# EFM32GG380F1024 register map
File version: 5.8.2
CPU: CM3 r2p1, little endian, MPU, no FPU, 3 interrupt priority bits
Registers are 32-bit, read-write, reset 0x0 unless marked. A register's access mark holds for its fields unless they carry their own. Offsets are from the block's base; [hi:lo] are bit positions; {n}, {i} and the like mark numbered series; 'fields as' and 'values as' point back to an identical list.

## EMU
Base 0x400C6000
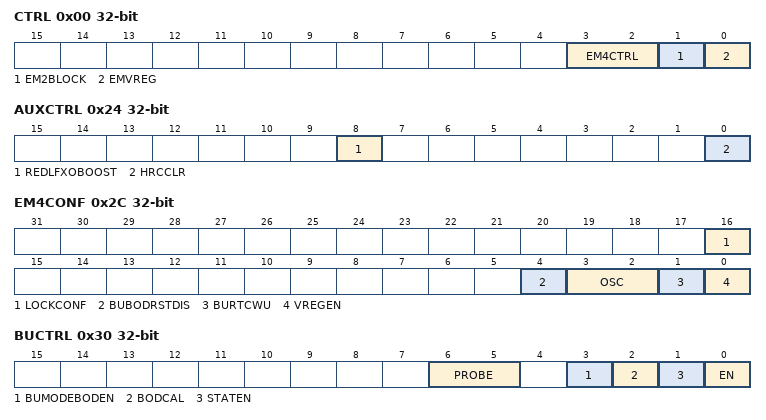
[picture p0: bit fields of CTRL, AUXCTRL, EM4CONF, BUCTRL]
0x00 CTRL — Control Register
  [3:2] EM4CTRL — Energy Mode 4 Control
  [1] EM2BLOCK — Energy Mode 2 Block
  [0] EMVREG — Energy Mode Voltage Regulator Control
0x04 MEMCTRL — Memory Control Register
  [2:0] POWERDOWN — RAM block power-down
    4=BLK3 (Power down RAM block 3 (address range 0x20018000-0x2001FFFF).); 6=BLK23 (Power down RAM blocks 2-3 (address range 0x20010000-0x2001FFFF).); 7=BLK123 (Power down RAM blocks 1-3 (address range 0x20008000-0x2001FFFF).)
0x08 LOCK — Configuration Lock Register
  [15:0] LOCKKEY — Configuration Lock Key
    0=UNLOCKED; 1=LOCKED
0x24 AUXCTRL — Auxiliary Control Register
  [8] REDLFXOBOOST — Reduce LFXO Start-up Boost Current
  [0] HRCCLR — Hard Reset Cause Clear
0x2C EM4CONF — Energy mode 4 configuration register
  [16] LOCKCONF — EM4 configuration lock enable
  [4] BUBODRSTDIS — Disable reset from Backup BOD in EM4
  [3:2] OSC — Select EM4 duty oscillator
    0=ULFRCO (ULFRCO is available.); 1=LFRCO (LFRCO is available. Can only be set if LFRCO is running before EM4/backup entry.); 2=LFXO (LFXO is available. Can only be set if LFXO is available before EM4/backup entry.)
  [1] BURTCWU — Backup RTC EM4 wakeup enable
  [0] VREGEN — EM4 voltage regulator enable
0x30 BUCTRL — Backup Power configuration register
  [6:5] PROBE — Voltage probe select
    0=DISABLE (Disable voltage probe.); 1=VDDDREG (Connect probe to VDD_DREG.); 2=BUIN (Connect probe to BU_IN.); 3=BUOUT (Connect probe to BU_OUT.)
  [3] BUMODEBODEN — Enable brown out detection on BU_VIN when in backup mode
  [2] BODCAL — Enable BOD calibration mode
  [1] STATEN — Enable backup mode status export
  [0] EN — Enable backup mode
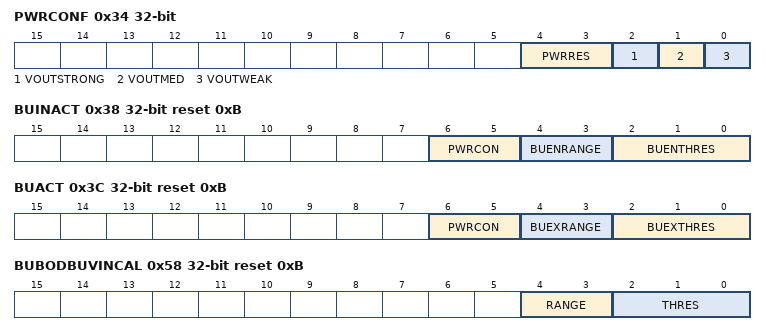
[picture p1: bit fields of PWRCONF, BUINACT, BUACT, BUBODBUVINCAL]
0x34 PWRCONF — Power connection configuration register
  [4:3] PWRRES — Power domain resistor select
    {v}=RES{v} (Main power and backup power connected with RES{v} series resistance.) (v=0..3)
  [2] VOUTSTRONG — BU_VOUT strong enable
  [1] VOUTMED — BU_VOUT medium enable
  [0] VOUTWEAK — BU_VOUT weak enable
0x38 BUINACT reset 0xB — Backup mode inactive configuration register
  [6:5] PWRCON — Power connection configuration when not in Backup mode
    0=NONE (No connection.); 1=BUMAIN (Main power and backup power are connected through a diode, allowing current to flow from backup power source to main power source, but not the other way.); 2=MAINBU (Main power and backup power are connected through a diode, allowing current to flow from main power source to backup power source, but not the other way.); 3=NODIODE (Main power and backup power are connected without diode.)
  [4:3] BUENRANGE
  [2:0] BUENTHRES
0x3C BUACT reset 0xB — Backup mode active configuration register
  [6:5] PWRCON — Power connection configuration when in Backup mode
    values as BUINACT.PWRCON
  [4:3] BUEXRANGE
  [2:0] BUEXTHRES
0x40 STATUS ro
  [0] BURDY — Backup mode ready
0x44 ROUTE reset 0x1 — I/O Routing Register
  [0] BUVINPEN — BU_VIN Pin Enable
0x48 IF ro — Interrupt Flag Register
  [0] BURDY — Backup functionality ready Interrupt Flag
0x4C IFS wo — Interrupt Flag Set Register
  [0] BURDY — Set Backup functionality ready Interrupt Flag
0x50 IFC wo — Interrupt Flag Clear Register
  [0] BURDY — Clear Backup functionality ready Interrupt Flag
0x54 IEN — Interrupt Enable Register
  [0] BURDY — Backup functionality ready Interrupt Enable
0x58 BUBODBUVINCAL reset 0xB — BU_VIN Backup BOD calibration
  [4:3] RANGE, [2:0] THRES
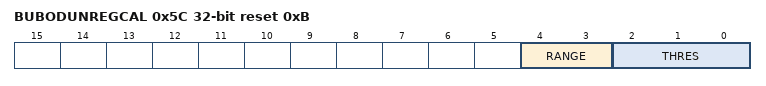
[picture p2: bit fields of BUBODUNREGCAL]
0x5C BUBODUNREGCAL reset 0xB — Unregulated power Backup BOD calibration
  [4:3] RANGE, [2:0] THRES

## RMU
Base 0x400CA000
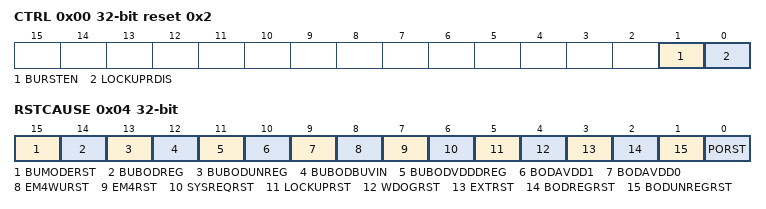
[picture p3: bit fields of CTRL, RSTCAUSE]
0x00 CTRL reset 0x2 — Control Register
  [1] BURSTEN — Backup domain reset enable
  [0] LOCKUPRDIS — Lockup Reset Disable
0x04 RSTCAUSE ro — Reset Cause Register
  [15] BUMODERST — Backup mode reset
  [14] BUBODREG — Backup Brown Out Detector Regulated Domain
  [13] BUBODUNREG — Backup Brown Out Detector Unregulated Domain
  [12] BUBODBUVIN — Backup Brown Out Detector, BU_VIN
  [11] BUBODVDDDREG — Backup Brown Out Detector, VDD_DREG
  [10] BODAVDD1 — AVDD1 Bod Reset
  [9] BODAVDD0 — AVDD0 Bod Reset
  [8] EM4WURST — EM4 Wake-up Reset
  [7] EM4RST — EM4 Reset
  [6] SYSREQRST — System Request Reset
  [5] LOCKUPRST — LOCKUP Reset
  [4] WDOGRST — Watchdog Reset
  [3] EXTRST — External Pin Reset
  [2] BODREGRST — Brown Out Detector Regulated Domain Reset
  [1] BODUNREGRST — Brown Out Detector Unregulated Domain Reset
  [0] PORST — Power On Reset
0x08 CMD wo — Command Register
  [0] RCCLR — Reset Cause Clear
